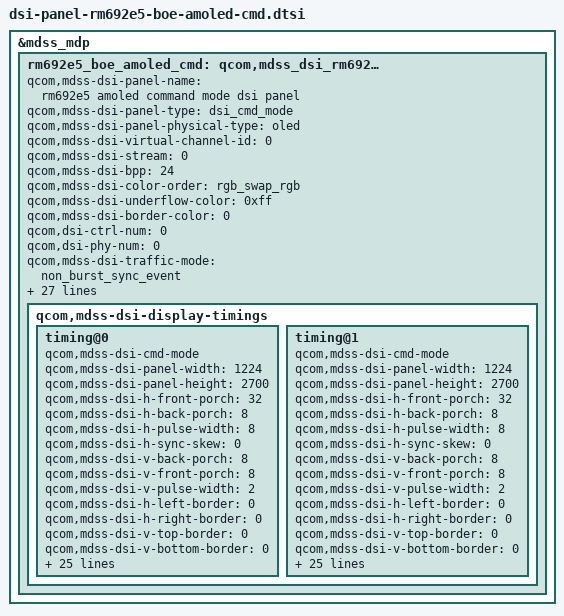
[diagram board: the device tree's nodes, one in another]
&mdss_mdp {
	rm692e5_boe_amoled_cmd: qcom,mdss_dsi_rm692e5_boe_amoled_cmd {
		qcom,mdss-dsi-panel-name = "rm692e5 amoled command mode dsi panel";
			
		qcom,mdss-dsi-panel-type = "dsi_cmd_mode";
		qcom,mdss-dsi-panel-physical-type = "oled";
		qcom,mdss-dsi-virtual-channel-id = <0>;
		qcom,mdss-dsi-stream = <0>;
		qcom,mdss-dsi-bpp = <24>;
		qcom,mdss-dsi-color-order = "rgb_swap_rgb";
		qcom,mdss-dsi-underflow-color = <0xff>;
		qcom,mdss-dsi-border-color = <0>;
		qcom,dsi-ctrl-num = <0>;
		qcom,dsi-phy-num = <0>;

		qcom,mdss-dsi-traffic-mode = "non_burst_sync_event";
		qcom,mdss-dsi-lane-map = "lane_map_0123";
		qcom,mdss-dsi-bllp-eof-power-mode;
		qcom,mdss-dsi-bllp-power-mode;

		qcom,mdss-dsi-lp11-init;		
		qcom,mdss-dsi-lane-0-state;
		qcom,mdss-dsi-lane-1-state;
		qcom,mdss-dsi-lane-2-state;
		qcom,mdss-dsi-lane-3-state;	
		qcom,mdss-dsi-dma-trigger = "trigger_sw";
		qcom,mdss-dsi-mdp-trigger = "none";
		qcom,mdss-dsi-reset-sequence = <1 10>, <0 5>, <1 10>;
		qcom,mdss-dsi-te-pin-select = <1>;
		qcom,mdss-dsi-wr-mem-start = <0x2c>;
		qcom,mdss-dsi-wr-mem-continue = <0x3c>;		
		qcom,mdss-dsi-te-dcs-command = <1>;
		qcom,mdss-dsi-te-check-enable;
		qcom,mdss-dsi-te-using-te-pin;
		qcom,mdss-dsi-t-clk-post = <0x8a>;//0x9f
		qcom,mdss-dsi-t-clk-pre = <0x0c>;//0x0f

		qcom,mdss-dsi-panel-hdr-enabled;
		qcom,mdss-dsi-panel-hdr-color-primaries = <14500 15500 32000
			17000 15500 30000 8000 3000>;
		qcom,mdss-dsi-panel-peak-brightness = <8000000>;
		qcom,mdss-dsi-panel-blackness-level = <3230>;

		qcom,dynamic-mode-switch-enabled;
		qcom,dynamic-mode-switch-type = "dynamic-resolution-switch-immediate";

		qcom,mdss-dsi-display-timings {
			timing@0 {
				qcom,mdss-dsi-cmd-mode;
				qcom,mdss-dsi-panel-width = <1224>;
				qcom,mdss-dsi-panel-height = <2700>;
				qcom,mdss-dsi-h-front-porch = <32>;
				qcom,mdss-dsi-h-back-porch = <8>;
				qcom,mdss-dsi-h-pulse-width = <8>;

				qcom,mdss-dsi-h-sync-skew = <0>;
				qcom,mdss-dsi-v-back-porch = <8>;
				qcom,mdss-dsi-v-front-porch = <8>;
				qcom,mdss-dsi-v-pulse-width = <2>;

				qcom,mdss-dsi-h-left-border = <0>;
				qcom,mdss-dsi-h-right-border = <0>;
				qcom,mdss-dsi-v-top-border = <0>;
				qcom,mdss-dsi-v-bottom-border = <0>;

				qcom,mdss-dsi-panel-jitter = <0x4 0x1>;
				qcom,mdss-dsi-panel-framerate = <60>;
				qcom,mdss-dsi-on-command = [
					29 01 00 00 01 00 02 FE 41
					29 01 00 00 01 00 02 D6 00
					29 01 00 00 01 00 02 FE 16
					29 01 00 00 01 00 02 8A 87
					29 01 00 00 01 00 02 FE 71
					29 01 00 00 01 00 02 82 01		
					29 01 00 00 01 00 02 C6 00
					29 01 00 00 01 00 02 C7 2C 
					29 01 00 00 01 00 02 C8 64
					29 01 00 00 01 00 02 C9 3C
					29 01 00 00 01 00 02 CA 80 
					29 01 00 00 01 00 02 CB 02
					29 01 00 00 01 00 02 CC 02					
					29 01 00 00 01 00 02 FE 38
					29 01 00 00 01 00 02 18 13
					29 01 00 00 01 00 02 FE F4
					29 01 00 00 01 00 02 00 FF
					29 01 00 00 01 00 02 01 FF
					29 01 00 00 01 00 02 02 CF
					29 01 00 00 01 00 02 03 BC
					29 01 00 00 01 00 02 04 B9
					29 01 00 00 01 00 02 05 99
					29 01 00 00 01 00 02 06 02
					29 01 00 00 01 00 02 07 0A
					29 01 00 00 01 00 02 08 E0
					29 01 00 00 01 00 02 09 4C
					29 01 00 00 01 00 02 0A EB
					29 01 00 00 01 00 02 0B E8	
					29 01 00 00 01 00 02 0C 32
					29 01 00 00 01 00 02 0D 07
					29 01 00 00 01 00 02 FE F4
					29 01 00 00 01 00 02 0D C0
					29 01 00 00 01 00 02 0E FF
					29 01 00 00 01 00 02 0F FF
					29 01 00 00 01 00 02 10 33
					29 01 00 00 01 00 02 11 6F
					29 01 00 00 01 00 02 12 6E
					29 01 00 00 01 00 02 13 A6
					29 01 00 00 01 00 02 14 80
					29 01 00 00 01 00 02 15 02
					29 01 00 00 01 00 02 16 38
					29 01 00 00 01 00 02 17 D3
					29 01 00 00 01 00 02 18 3A
					29 01 00 00 01 00 02 19 BA	
					29 01 00 00 01 00 02 1A CC
					29 01 00 00 01 00 02 1B 01
						  05 01 00 00 20 00 02 00 00
					29 01 00 00 01 00 02 FE 38      
					29 01 00 00 01 00 02 18 13
					29 01 00 00 01 00 02 FE D1
					29 01 00 00 01 00 02 D3 00
					29 01 00 00 01 00 02 D0 00
					29 01 00 00 01 00 02 D2 00
					29 01 00 00 01 00 02 D4 00
					29 01 00 00 01 00 02 B4 01
					29 01 00 00 01 00 02 FE F9 
					29 01 00 00 01 00 02 00 AF
					29 01 00 00 01 00 02 1D 37
					29 01 00 00 00 00 03 44 0A 7B					
					29 01 00 00 01 00 02 FE 00					
					29 01 00 00 01 00 02 FA 01					
					29 01 00 00 01 00 02 C2 08
					29 01 00 00 01 00 02 35 00					
					29 01 00 00 01 00 03 51 05 42	
						  05 01 00 00 64 00 02 11 00			    
						  05 01 00 00 01 00 02 29 00
				];

				qcom,mdss-dsi-off-command = [
					29 01 00 00 01 00 02 FE 00
					05 01 00 00 01 00 02 28 00
					05 01 00 00 64 00 02 10 00
				];

				qcom,mdss-dsi-lp1-command = [
					29 01 00 00 01 00 02 FE 00
					   05 01 00 00 01 00 01 39
					29 01 00 00 01 00 03 51 01 B1    
				];

				qcom,mdss-dsi-nolp-command = [
					29 01 00 00 01 00 02 FE 00
					   05 01 00 00 00 00 01 38 
				];

				qcom,mdss-dsi-timing-switch-command = [
					29 01 00 00 01 00 02 FE 40
					29 01 00 00 00 00 02 BD 00
					29 01 00 00 01 00 02 FE 00
				]; 

				qcom,mdss-dsi-on-command-state = "dsi_lp_mode";
				qcom,mdss-dsi-off-command-state = "dsi_hs_mode";
				qcom,mdss-dsi-lp1-command-state = "dsi_lp_mode";	
				qcom,mdss-dsi-nolp-command-state = "dsi_lp_mode";
				qcom,mdss-dsi-timing-switch-command-state = "dsi_hs_mode";

				qcom,compression-mode = "dsc";
				qcom,mdss-dsc-slice-height = <60>;
				qcom,mdss-dsc-slice-width = <1224>;
				qcom,mdss-dsc-slice-per-pkt = <2>;
				qcom,mdss-dsc-bit-per-component = <8>;
				qcom,mdss-dsc-bit-per-pixel = <8>;
				qcom,mdss-dsc-block-prediction-enable;				
			};

			timing@1 {
				qcom,mdss-dsi-cmd-mode;
				qcom,mdss-dsi-panel-width = <1224>;
				qcom,mdss-dsi-panel-height = <2700>;
				qcom,mdss-dsi-h-front-porch = <32>;
				qcom,mdss-dsi-h-back-porch = <8>;
				qcom,mdss-dsi-h-pulse-width = <8>;
				
				qcom,mdss-dsi-h-sync-skew = <0>;
				qcom,mdss-dsi-v-back-porch = <8>;
				qcom,mdss-dsi-v-front-porch = <8>;
				qcom,mdss-dsi-v-pulse-width = <2>;

				qcom,mdss-dsi-h-left-border = <0>;
				qcom,mdss-dsi-h-right-border = <0>;
				qcom,mdss-dsi-v-top-border = <0>;
				qcom,mdss-dsi-v-bottom-border = <0>;

				qcom,mdss-dsi-panel-jitter = <0x4 0x1>;
				qcom,mdss-dsi-panel-framerate = <90>;
				qcom,mdss-dsi-on-command = [
					29 01 00 00 01 00 02 FE 41
					29 01 00 00 01 00 02 D6 00
					29 01 00 00 01 00 02 FE 16
					29 01 00 00 01 00 02 8A 87
					29 01 00 00 01 00 02 FE 71
					29 01 00 00 01 00 02 82 01		
					29 01 00 00 01 00 02 C6 00
					29 01 00 00 01 00 02 C7 2C 
					29 01 00 00 01 00 02 C8 64
					29 01 00 00 01 00 02 C9 3C
					29 01 00 00 01 00 02 CA 80 
					29 01 00 00 01 00 02 CB 02
					29 01 00 00 01 00 02 CC 02
					29 01 00 00 01 00 02 FE 38
					29 01 00 00 01 00 02 18 13
					29 01 00 00 01 00 02 FE F4
					29 01 00 00 01 00 02 00 FF
					29 01 00 00 01 00 02 01 FF
					29 01 00 00 01 00 02 02 CF
					29 01 00 00 01 00 02 03 BC
					29 01 00 00 01 00 02 04 B9
					29 01 00 00 01 00 02 05 99
					29 01 00 00 01 00 02 06 02
					29 01 00 00 01 00 02 07 0A
					29 01 00 00 01 00 02 08 E0
					29 01 00 00 01 00 02 09 4C
					29 01 00 00 01 00 02 0A EB
					29 01 00 00 01 00 02 0B E8	
					29 01 00 00 01 00 02 0C 32
					29 01 00 00 01 00 02 0D 07
					29 01 00 00 01 00 02 FE F4
					29 01 00 00 01 00 02 0D C0
					29 01 00 00 01 00 02 0E FF
					29 01 00 00 01 00 02 0F FF
					29 01 00 00 01 00 02 10 33
					29 01 00 00 01 00 02 11 6F
					29 01 00 00 01 00 02 12 6E
					29 01 00 00 01 00 02 13 A6
					29 01 00 00 01 00 02 14 80
					29 01 00 00 01 00 02 15 02
					29 01 00 00 01 00 02 16 38
					29 01 00 00 01 00 02 17 D3
					29 01 00 00 01 00 02 18 3A
					29 01 00 00 01 00 02 19 BA	
					29 01 00 00 01 00 02 1A CC
					29 01 00 00 01 00 02 1B 01
						  05 01 00 00 20 00 02 00 00
					29 01 00 00 01 00 02 FE 38      
					29 01 00 00 01 00 02 18 13
					29 01 00 00 01 00 02 FE D1
					29 01 00 00 01 00 02 D3 00
					29 01 00 00 01 00 02 D0 00
					29 01 00 00 01 00 02 D2 00
					29 01 00 00 01 00 02 D4 00
					29 01 00 00 01 00 02 B4 01
					29 01 00 00 01 00 02 FE F9 
					29 01 00 00 01 00 02 00 AF
					29 01 00 00 01 00 02 1D 37
					29 01 00 00 00 00 03 44 0A 7B					
					29 01 00 00 01 00 02 FE 00					
					29 01 00 00 01 00 02 FA 01					
					29 01 00 00 01 00 02 C2 08
					29 01 00 00 01 00 02 35 00					
					29 01 00 00 01 00 03 51 05 42	
						  05 01 00 00 64 00 02 11 00			    
						  05 01 00 00 01 00 02 29 00
				];

				qcom,mdss-dsi-off-command = [
					29 01 00 00 01 00 02 FE 00
					05 01 00 00 01 00 02 28 00
					05 01 00 00 64 00 02 10 00
				];

				qcom,mdss-dsi-lp1-command = [
					29 01 00 00 01 00 02 FE 00
					   05 01 00 00 01 00 01 39
					29 01 00 00 01 00 03 51 01 B1    
				];

				qcom,mdss-dsi-nolp-command = [
					29 01 00 00 01 00 02 FE 00
					   05 01 00 00 00 00 01 38 
				];

				qcom,mdss-dsi-timing-switch-command = [
					29 01 00 00 01 00 02 FE 40
					29 01 00 00 00 00 02 BD 05
					29 01 00 00 01 00 02 FE 00
				];

				qcom,mdss-dsi-on-command-state = "dsi_lp_mode";
				qcom,mdss-dsi-off-command-state = "dsi_hs_mode";
				qcom,mdss-dsi-lp1-command-state = "dsi_lp_mode";
				qcom,mdss-dsi-nolp-command-state = "dsi_lp_mode";
				qcom,mdss-dsi-timing-switch-command-state = "dsi_hs_mode";

				qcom,compression-mode = "dsc";
				qcom,mdss-dsc-slice-height = <60>;
				qcom,mdss-dsc-slice-width = <1224>;
				qcom,mdss-dsc-slice-per-pkt = <2>;
				qcom,mdss-dsc-bit-per-component = <8>;
				qcom,mdss-dsc-bit-per-pixel = <8>;
				qcom,mdss-dsc-block-prediction-enable;				
			};							
		};
	};
};


